# PCIE1_CORE_DBN_CFG_PCIE_CORE register map
Vendor: Texas Instruments
Peripheral module from a debugger description file (folder J721S2).
Registers are 32-bit, read-write, reset 0x0 unless marked. A register's access mark holds for its fields unless they carry their own. Offsets are as the file gives them; lines under a group give offsets from that group; [hi:lo] are bit positions; {n}, {i} and the like mark numbered series; 'fields as' and 'values as' point back to an identical list; <NAME> marks a mode.

## PCIE1_CORE_DBN_CFG_PCIE_CORE (part 1 of 7)
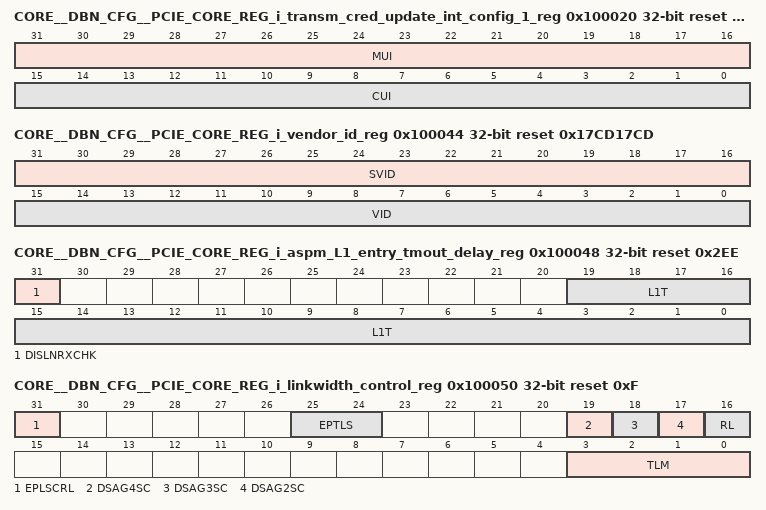
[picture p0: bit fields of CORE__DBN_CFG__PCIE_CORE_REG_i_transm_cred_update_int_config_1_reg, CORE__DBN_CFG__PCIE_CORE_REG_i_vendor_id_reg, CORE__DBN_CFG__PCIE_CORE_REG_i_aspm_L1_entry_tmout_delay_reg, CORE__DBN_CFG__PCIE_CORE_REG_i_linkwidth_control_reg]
0x100020 CORE__DBN_CFG__PCIE_CORE_REG_i_transm_cred_update_int_config_1_reg reset 0x3AA0004 — This register contains parameters that control how frequently the Controller sends a credit update to the opposite node.
  [31:16] MUI — Maximum credit update interval for all transactions. If no new credit has become available since the last update, the Controller will repeat the last update after this interval. This is to recover from any losses of credit update packets. The value is in units of 16 ns. This field could be re-written by the internal logic when the negotiated link width or link speed changes, to correspond to the default values defined in defines.h. The user may override this default value by writing into this register field. The value written will be lost on a change in the negotiated link width/speed.
  [15:0] CUI — Minimum credit update interval for Completion packets. The Controller follows this minimum interval between issuing completion credit updates on the link. This is to limit the bandwidth use of credit updates. If new credit becomes available in the receive FIFO since the last update was sent, the Controller will issue a new update only after this interval has elapsed since the last update. The value is in units of 16 ns. This parameter is not used when the Completion credit is infinity.
0x100024 CORE__DBN_CFG__PCIE_CORE_REG_i_L0S_timeout_limit_reg reset 0x177 — This register defines the timeout value for transitioning to the L0S power state. If the transmit side has been idle for this interval, the Controller will transmit the idle sequence on the link and transition the state of the link to L0S .
  [15:0] LT — Contains the timeout value [in units of 16 ns] for transitioning to the L0S power state. Setting this parameter to 0 permanently disables the transition to the L0S power state.
0x100028 CORE__DBN_CFG__PCIE_CORE_REG_i_transmit_tlp_count_reg access not given — This register contains the number of Transaction-Layer packets transmitted by the Controller on the link since the register was last reset. This counter saturates on reaching a count of all 1's. Writing all 1's to this register causes it to be reset to 0.
  [31:0] TTC — Count of TLPs transmitted (access R/W1TC)
0x10002C CORE__DBN_CFG__PCIE_CORE_REG_i_transmit_tlp_payload_dword_count_reg access not given — This register contains the aggregate number of payload double-words transmitted in Transaction-Layer Packets by the Controller on the link since the register was last reset. This counter saturates on reaching a count of all 1's. Writing all 1's to this register causes it to be reset to 0.
  [31:0] TTPBC — Count of TLPs payload Dwords transmitted (access R/W1TC)
0x100030 CORE__DBN_CFG__PCIE_CORE_REG_i_receive_tlp_count_reg access not given — This register contains the number of Transaction-Layer packets received by the Controller from the link since the register was last reset. This counter saturates on reaching a count of all 1's. Writing all 1's to this register causes it to be reset to 0.
  [31:0] RTC — Count of TLPs received (access R/W1TC)
0x100034 CORE__DBN_CFG__PCIE_CORE_REG_i_receive_tlp_payload_dword_count_reg access not given — This register contains the aggregate number of payload double-words received in Transaction-Layer packets by the Controller from the link since the register was last reset. This counter saturates on reaching a count of all 1's. Writing all 1's to this register causes it to be reset to 0.
  [31:0] RTPDC — Count of TLP payload Dwords received (access R/W1TC)
0x100038 CORE__DBN_CFG__PCIE_CORE_REG_i_compln_tmout_lim_0_reg reset 0xBEBC20 — This register contains the timeout value used to detect a completion timeout event for a request originated by the Controller from it master interface, when sub-range 1 is programmed in the Device Control 2 Register.
  [23:0] CTL — Timeout limit for completion timers [in 4 ns cycles]. Default value is 50 ms in 4 ns cycles. Please note that there could be a variation of 0 to +8us on the programmed Completion Timeout.
0x10003C CORE__DBN_CFG__PCIE_CORE_REG_i_compln_tmout_lim_1_reg reset 0x2FAF080 — This register contains the timeout value used to detect a completion timeout event for a request originated by the Controller from its master interface, when sub-range 2 is programmed in the Device Control 2 Register.
  [27:0] CTL — Timeout limit for completion timers [in 4 ns cycles]. Default value is 200ms in 4ns cycles. Please note that there could be a variation of 0 to +8us on the programmed Completion Timeout.
0x100040 CORE__DBN_CFG__PCIE_CORE_REG_i_L1_st_reentry_delay_reg — This register specifies the time the Controller will wait before it re-enters the L1 state if its link partner transitions the link to L0 while all the Functions of the Controller are in D3 power state. The Controller will change the power state of the link from L0 to L1 if no activity is detected both on the transmit and receive sides before this interval, while all Functions are in D3 state and the link is in L0. Setting this register to 0 disables re-entry to L1 state if the link partner returns the link to L0 from L1 when all the Functions of the Controller are in D3 state. This register controls only the re-entry to L1. The initial transition to L1 always occurs when all of the Functions of the Controller are set to the D3 state.
  [31:0] L1RD — Delay to re-enter L1 after no activity [in units of 16 ns].
0x100044 CORE__DBN_CFG__PCIE_CORE_REG_i_vendor_id_reg reset 0x17CD17CD — This register contains the Vendor ID and Subsystem Vendor ID that the device advertises during its enumeration of the PCI configuration space.
  [31:16] SVID — Subsystem Vendor ID
  [15:0] VID — Vendor ID
0x100048 CORE__DBN_CFG__PCIE_CORE_REG_i_aspm_L1_entry_tmout_delay_reg reset 0x2EE — This register defines the timeout value for transitioning to the L1 power state under Active State Power management. If the transmit side has been idle for this interval, the Controller will initiate a transition of its link to the L1 power state.
  [31] DISLNRXCHK — This bit is used to configure the ASPM L1 Entry mechanism: 1: Link is checked for IDLE only on the TX to determine ASPM L1 Entry. ASPM L1 entry is initiated if no TLP is transmitted for the L1 timeout period. 0: Link is checked for IDLE both on the TX and RX to determine ASPM L1 Entry. ASPM L1 entry is initiated if no TLP is transmitted/received for the L1 timeout period.
  [19:0] L1T — Contains the timeout value[in units of 16 ns] for transitioning to the L1 power state. Setting it to 0 permanently disables the transition to the L1 power state.
0x10004C CORE__DBN_CFG__PCIE_CORE_REG_i_pme_turnoff_ack_delay_reg reset 0x64 — Defines the time interval between the Controller receiving a PME_Turn_Off message from the link and generating an ack for it.
  [15:0] PTOAD — Time in microseconds between the Controller receiving a PME_TurnOff message TLP and the Controller sending a PME_TO_Ack response to it. This field must be set to a non-zero value in order for the Controller to send a response. Setting this field to 0 suppresses the Controller's response to PME_TurnOff message, so that the client may transmit the PME_TO_Ack message through the master interface.
0x100050 CORE__DBN_CFG__PCIE_CORE_REG_i_linkwidth_control_reg reset 0xF — This register can be used to retrain the link to a different width, without bringing the link down. This register can also be used to retrain the link to a different speed, without bringing the link down.
  [31] EPLSCRL — Writing a 1 into this field results in the Controller re-training the link to change its speed. When setting this bit to 1, the software must also set the EP Target Link Speed field to indicate the speed that the EP desires to change on the link. The EP Controller will attempt to change the link to this speed. This bit is cleared by the internal logic of the Controller after the re-training has been completed and link has reached the L0 state. Software must wait for the bit to be clear before setting it again to change the link speed.
  [25:24] EPTLS — This field contains the Link Speed that the EP intends to change to during the re-training. Client needs to ensure that this field is programmed to a speed which is lesser than or equal to the Target Link Speed field of PF0 Configuration Link Control 2 Register. Client also needs to ensure that this does not exceed PCIE_GENERATION_SEL strap input. Defined encodings of this field are: 00 - GEN1 01 - GEN2 10 - GEN3 11 - GEN4
  [19] DSAG4SC — This bit is used Only in RP mode. This bit is not used in EP mode of the Controller. During initial link training, if both components advertise Gen4 capability and if Gen3 speed change, equalization was successful, the Controller [RP] autonomously initiates Gen3 to Gen4 speed change, equalization. If Gen4 autonomous speed change/equalization was unsuccessful, then the Link transitions back to Gen3 L0. Software can re-initiate Gen4 speed change. Autonomous Speed Change to Gen4 can be disabled by programming this bit to 1. Note: If Disable Auto Gen3 Speed Change is disabled, then Auto Gen4 Speed Change must also be disabled by setting this bit to 1.
  [18] DSAG3SC — This bit is used Only in RP mode. This bit is not used in EP mode of the Controller. During initial link training, if both components advertise Gen3 capability, the Controller [RP] autonomously initiates Gen1 to Gen3 speed change, equalization. If Gen3 autonomous speed change/equalization was unsuccessful, then the Link transitions back to Gen1 L0. Software can re-initiate Gen3 speed change. Autonomous Speed Change to Gen3 can be disabled by programming this bit to 1.
  [17] DSAG2SC — This bit is used Only in RP mode. This bit is not used in EP mode of the Controller. During initial link training, if both components advertise Gen2 capability and if Gen2 is the highest common supported speed the Controller [RP] autonomously initiates Gen1 to Gen2 speed change. If Gen2 autonomous speed change was unsuccessful, then the Link transitions back to Gen1 L0. Software can re-initiate Gen2 speed change. Autonomous Speed Change to Gen2 can be disabled by programming this bit to 1.
  [16] RL — Writing a 1 into this field results in the Controller re-training the link to change its width. When setting this bit to 1, the software must also set the target lane-map field to indicate the lanes it desires to be part of the link. The Controller will attempt to form a link with this set of lanes. The link formed at the end of the retraining may include all of these lanes [if both nodes agree on them during re-training], or the largest subset that both sides were able to activate. This bit is cleared by the internal logic of the Controller after the re-training has been completed and link has reached the L0 state. Software must wait for the bit to be clear before setting it again to change the link width.
  [3:0] TLM — This field contains the bitmap of the lanes to be included in forming the link during the re-training. 0001 - Retrain to a x1 link 0011 - Retrain to a x2 link 1111 - Retrain to a x4 link If the target lane map includes lanes that were inactive when retraining is initiated, then both the Controller and its link partner must support the LinkWidth Upconfigure Capability to be able to activate those lanes. In RC Mode, the user can check if the remote node has this capability by reading the Remote Link Upconfigure Capability Status bit in Physical Layer Configuration Register 0 after the link first came up.
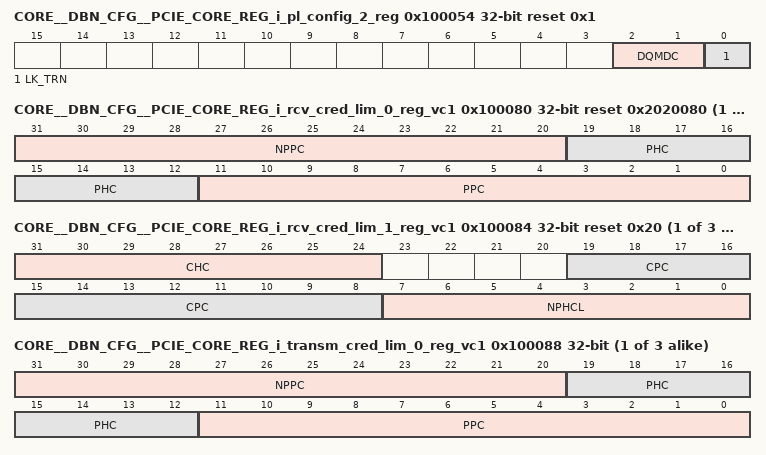
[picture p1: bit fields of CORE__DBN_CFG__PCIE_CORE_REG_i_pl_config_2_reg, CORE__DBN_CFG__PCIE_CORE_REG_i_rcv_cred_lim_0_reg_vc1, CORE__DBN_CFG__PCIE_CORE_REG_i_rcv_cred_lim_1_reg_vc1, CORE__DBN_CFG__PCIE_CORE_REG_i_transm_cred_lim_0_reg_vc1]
0x100054 CORE__DBN_CFG__PCIE_CORE_REG_i_pl_config_2_reg reset 0x1 — This register controls various LTSSM related capabilities.
  [2:1] DQMDC — As per PCIe specification, All Receivers must meet the the Z-RX-DC specification for 2.5 GT/s within 1ms of entering Detect.Quiet LTSSM substate. The LTSSM must stay in this substate until the ZRX-DC specification for 2.5 GT/s is met. This register field can be used to program the minimum time that LTSSM waits on entering Detect.Quiet state. 00 : 0us minimum wait time in Detect.Quiet state. 01 : 100us minimum wait time in Detect.Quiet state. 10 : 1ms minimum wait time in Detect.Quiet state. 11 : 2ms minimum wait time in Detect.Quiet state.
  [0] LK_TRN — This bit is AND'ed with the input LINK_TRAINING_ENABLE strap to enable Link Training.
0x100070 CORE__DBN_CFG__PCIE_CORE_REG_i_multi_vc_conrol_reg reset 0x2 — This register contains control bits to control certain multi VC features
  [1] WAIT_4_ALL_VC_CC_RDY — When this bit is set, the controller waits for credits to be available to be able to send atleast 1 max payload TLP in all enabled VCs. When this bit is not set, the controller waits for credits to be available to be able to send atleast 1 max payload TLP in any of the enabled VCs [PCI-SIG recommedned].
0x100074 CORE__DBN_CFG__PCIE_CORE_REG_i_sris_control_reg — This register contains control bits to enable the SRIS operation in the PHY Layer
  [0] SRISE — Setting this bit enables SRIS mode in the PHY layer. This bit should be changed before link training begins by holding the LINK_TRAINING_ENABLE input to 1'b0. When SRIS is disabled using this bit the Lower SKP OS Generation Supported Speeds Vector and Lower SKP OS Reception Supported Speeds Vector in the Link Capabilities Register 2 will be forced to ZERO. The default value of this register can be controlled using the SRIS_ENABLE strap input.
{0x100070+0x10*i} CORE__DBN_CFG__PCIE_CORE_REG_i_rcv_cred_lim_0_reg_vc{i} reset 0x2020080 (i=1..3) — This register contains the initial credit limits advertised by the Controller during th DL initialization. If the fields of this register are modified, the link must be re-trained to re-initialize the DL for the modified settings to take effect. The credit limit fields in this register can be programmed to any value lesser than or equal to the respective default values. The default values are set to advertise the full size of the receive buffers. If a value of 0x00 is programmed, it implies infinite credit. Note: This may result in receiver overflow if received data is back pressured on the Client interface.
  [31:20] NPPC — Non-Posted payload credit limit advertised by the Controller for VC {i} . This field is in units of 4 DWords, 16 DWords or 64 DWords based on the Local Posted Payload Credit Scale for VC {i}. 00b => [units of 4 DWords] 01b => [units of 4 DWords] 10b => [units of 16 DWords] 11b => [units of 64 DWords] Note: When Scaled FLow Control is Activated, the programmed credit value is advertised in the InitFC DLLPs. Else, the programmed credit value is internally normalized to units of 4 DW and then advertised in the InitFC DLLPs. Caution: The programmed Header and Payload credit values must not exceed the actual size of the Receive Buffer.
  [19:12] PHC — Posted header credit limit advertised by the Controller for VC {i}. This field is in units of 1, 4 or 16 Packet Headers based on the Local Posted Header Credit Scale for VC {i}. 00b => [units of 1 Packet Header] 01b => [units of 1 Packet Header] 10b => [units of 4 Packet Headers] 11b => [units of 16 Packet Headers] Note: When Scaled FLow Control is Activated, the programmed credit value is advertised in the InitFC DLLPs. Else, the programmed credit value is internally normalized to units of [1 Packet Header] and then advertised in the InitFC DLLPs. Note: Packet Header represents one maximum-size TLP Header + TLP Digest + maximum number of EndEnd TLP Prefixes permitted in a TLP. Caution: The programmed Header and Payload credit values must not exceed the actual size of the Receive Buffer.
  [11:0] PPC — Posted payload credit limit advertised by the Controller for VC {i}. This field is in units of 4 DWords, 16 DWords or 64 DWords based on the Local Posted Payload Credit Scale for VC {i}. 00b => [units of 4 DWords] 01b => [units of 4 DWords] 10b => [units of 16 DWords] 11b => [units of 64 DWords] Note: When Scaled FLow Control is Activated, the programmed credit value is advertised in the InitFC DLLPs. Else, the programmed credit value is internally normalized to units of 4 DW and then advertised in the InitFC DLLPs. Caution: The programmed Header and Payload credit values must not exceed the actual size of the Receive Buffer.
{0x100074+0x10*i} CORE__DBN_CFG__PCIE_CORE_REG_i_rcv_cred_lim_1_reg_vc{i} reset 0x20 (i=1..3) — This register contains the initial credit limits advertised by the Controller during the DL initialization. If the fields of this register are modified, the link must be re-trained to re-initialize the DL for the modified settings to take effect. The credit limit fields in this register can be programmed to any value lesser than or equal to the respective default values. The default values are set to advertise the full size of the receive buffers. If a value of 0x00 is programmed, it implies infinite credit. Note: This may result in receiver overflow if received data is back pressured on the Client interface.
  [31:24] CHC — Completion header credit limit advertised by the Controller for VC {i} [in number of packets]. This field is in units of 1, 4 or 16 Packet Headers based on the Local Posted Header Credit Scale for VC {i}. 00b => [units of 1 Packet Header] 01b => [units of 1 Packet Header] 10b => [units of 4 Packet Headers] 11b => [units of 16 Packet Headers] Note: When Scaled FLow Control is Activated, the programmed credit value is advertised in the InitFC DLLPs. Else, the programmed credit value is internally normalized to units of [1 Packet Header] and then advertised in the InitFC DLLPs. Note: Packet Header represents one maximum-size TLP Header + TLP Digest + maximum number of EndEnd TLP Prefixes permitted in a TLP. Caution: The programmed Header and Payload credit values must not exceed the actual size of the Receive Buffer.
  [19:8] CPC — Completion payload credit limit advertised by the Controller for VC {i} . This field is in units of 4 DWords, 16 DWords or 64 DWords based on the Local Posted Payload Credit Scale for VC {i}. 00b => [units of 4 DWords] 01b => [units of 4 DWords] 10b => [units of 16 DWords] 11b => [units of 64 DWords] Note: When Scaled FLow Control is Activated, the programmed credit value is advertised in the InitFC DLLPs. Else, the programmed credit value is internally normalized to units of 4 DW and then advertised in the InitFC DLLPs. Caution: The programmed Header and Payload credit values must not exceed the actual size of the Receive Buffer.
  [7:0] NPHCL — Non-Posted header credit limit advertised by the Controller for VC {i} [in number of packets]. This field is in units of 1, 4 or 16 Packet Headers based on the Local Posted Header Credit Scale for VC {i}. 00b => [units of 1 Packet Header] 01b => [units of 1 Packet Header] 10b => [units of 4 Packet Headers] 11b => [units of 16 Packet Headers] Note: When Scaled FLow Control is Activated, the programmed credit value is advertised in the InitFC DLLPs. Else, the programmed credit value is internally normalized to units of [1 Packet Header] and then advertised in the InitFC DLLPs. Note: Packet Header represents one maximum-size TLP Header + TLP Digest + maximum number of EndEnd TLP Prefixes permitted in a TLP. Caution: The programmed Header and Payload credit values must not exceed the actual size of the Receive Buffer.
{0x100078+0x10*i} CORE__DBN_CFG__PCIE_CORE_REG_i_transm_cred_lim_0_reg_vc{i} ro (i=1..3) — This register contains the initial credit limits received from the opposite node during the DL initialization. It is a read-only register.
  [31:20] NPPC — Non-Posted payload credit limit received by the Controller for Link 0 . This field is in units of 4 DWords, 16 DWords or 64 DWords based on the Remote Posted Payload Credit Scale for VC {i}. 00b => [units of 4 DWords] 01b => [units of 4 DWords] 10b => [units of 16 DWords] 11b => [units of 64 DWords]
  [19:12] PHC — Posted header credit limit received by the Controller for this link . This field is in units of 1, 4 or 16 Packet Headers based on the Remote Posted Header Credit Scale for VC {i}. 00b => [units of 1 Packet Header] 01b => [units of 1 Packet Header] 10b => [units of 4 Packet Headers] 11b => [units of 16 Packet Headers] Note: Packet Header represents one maximum-size TLP Header + TLP Digest + maximum number of EndEnd TLP Prefixes permitted in a TLP.
  [11:0] PPC — Posted payload credit limit received by the Controller for this link . This field is in units of 4 DWords, 16 DWords or 64 DWords based on the Remote Posted Payload Credit Scale for VC {i}. 00b => [units of 4 DWords] 01b => [units of 4 DWords] 10b => [units of 16 DWords] 11b => [units of 64 DWords]
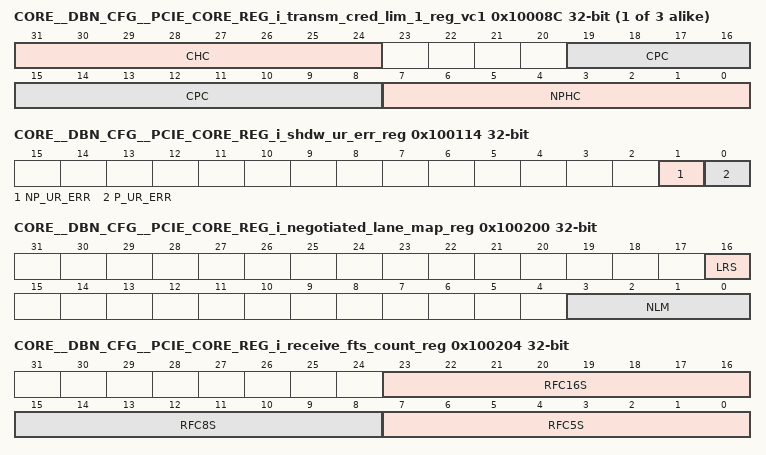
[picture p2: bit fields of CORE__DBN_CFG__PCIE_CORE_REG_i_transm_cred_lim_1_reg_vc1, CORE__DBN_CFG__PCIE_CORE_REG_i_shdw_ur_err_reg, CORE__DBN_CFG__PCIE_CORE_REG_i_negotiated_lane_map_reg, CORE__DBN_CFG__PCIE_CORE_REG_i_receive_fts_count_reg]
{0x10007C+0x10*i} CORE__DBN_CFG__PCIE_CORE_REG_i_transm_cred_lim_1_reg_vc{i} ro (i=1..3) — This register contains the initial credit limits received from the opposite node during the DL initialization. It is a read-only register.
  [31:24] CHC — Completion header credit limit received by the Controller for VC {i} . This field is in units of 1, 4 or 16 Packet Headers based on the Remote Posted Header Credit Scale for VC {i}. 00b => [units of 1 Packet Header] 01b => [units of 1 Packet Header] 10b => [units of 4 Packet Headers] 11b => [units of 16 Packet Headers] Note: Packet Header represents one maximum-size TLP Header + TLP Digest + maximum number of EndEnd TLP Prefixes permitted in a TLP.
  [19:8] CPC — Completion payload credit limit received by the Controller for VC {i} . This field is in units of 4 DWords, 16 DWords or 64 DWords based on the Remote Posted Payload Credit Scale for VC {i}. 00b => [units of 4 DWords] 01b => [units of 4 DWords] 10b => [units of 16 DWords] 11b => [units of 64 DWords]
  [7:0] NPHC — Non-Posted header credit limit received by the Controller for VC {i} . This field is in units of 1, 4 or 16 Packet Headers based on the Remote Posted Header Credit Scale for VC {i}. 00b => [units of 1 Packet Header] 01b => [units of 1 Packet Header] 10b => [units of 4 Packet Headers] 11b => [units of 16 Packet Headers] Note: Packet Header represents one maximum-size TLP Header + TLP Digest + maximum number of EndEnd TLP Prefixes permitted in a TLP.
0x1000F0 CORE__DBN_CFG__PCIE_CORE_REG_i_fc_init_delay_reg reset 0x64 — This register defines the delay value in between successive FC_INIT DLLPs for VCx.
  [15:0] FCINITDLY — Delay between successive sets of P, NP, CPL FC_INIT DLLP transmissions for VCx.
{0x100100+4i} CORE__DBN_CFG__PCIE_CORE_REG_i_shdw_hdr_log_{i}_reg (i=0..3)
  [31:0] SHDW_HDR_LOG_{i} — The value here will be reflected in the target function's header log register when f/w sets any bit in the the shadow error register. If the header log is already set in the function's AER space, the value here may not get written and a header log overflow bit would get set. This register holds [{32i+31}:{32i}] value of the TLP header.
0x100110 CORE__DBN_CFG__PCIE_CORE_REG_i_shdw_func_num_reg
  [7:0] SHDW_FUNC_NUM — The value here will be the target function number when f/w sets any bit in the shadow error register.
0x100114 CORE__DBN_CFG__PCIE_CORE_REG_i_shdw_ur_err_reg wo — Shadow register to create UR error via local f/w. Please make sure this register is written to last, after writing to all the header log and function number registers. A write to this register with any bits set, will internally create a single cycle pulse with the corresponding error type and the header log will reflect the value written in the shadow header log registers.
  [1] NP_UR_ERR — If this bit is set, the corresponding non-posted UR error bits will be set in the AER and device status registers of the target function.
  [0] P_UR_ERR — If this bit is set, the corresponding posted UR error bits will be set in the AER and device status registers of the target function.
0x100140 CORE__DBN_CFG__PCIE_CORE_REG_i_pm_clk_frequency_reg reset 0x19 — This register should be programmed with the frequency of the PM_CLK input to the Controller. The Controller supports the frequency range of 2MHz to 60MHz for PM_CLK. The reset value reflects the PM_CLK frequency chosen during Controller configuration. NOTE: PM_CLK will be timed at 60Mhz and the Controller SDC file will be generated accordingly. If timing is to be closed at a different frequency, then the user needs to update the SDC accordingly.
  [7:0] PMCLKFRQ — This field specifies the PM_CLK Frequency selected. The encoding is described below: 000000: Reserved 000001: Reserved 000010: PM_CLK is 2 MHz 000011: PM_CLK is 3 MHz 000100: PM_CLK is 4 MHz 000101: PM_CLK is 5 MHz .. 111010: PM_CLK is 58 MHz 111011: PM_CLK is 59 MHz 111100: PM_CLK is 60 MHz 111101 : Reserved 111110 : Reserved 111111 : Reserved .
{0x100140+4i} CORE__DBN_CFG__PCIE_CORE_REG_i_debug_dllp_count_gen{i}_reg ro (i=1..4) — This register indicates the total number of DLLPs received by the Controller in GEN{i}. This counter rolls over back to 0 after 4G DLLPs are received. This register can be used for Debug purposes.
  [31:0] DLLPCNT{i} — Reflects the total number of DLLPs received by the Controller at GEN{i} speed.
0x100158 CORE__DBN_CFG__PCIE_CORE_REG_i_vendor_defined_message_tag_reg — The 8-bit Tag field of the Outbound Vendor Defined Messages, transmitted by the Controller, can be programmed in this register.
  [7:0] VDMTAG — The Controller will use the tag programed in this register for all Outbound Vendor Defined Messages.
0x100200 CORE__DBN_CFG__PCIE_CORE_REG_i_negotiated_lane_map_reg ro — This register contains a map of the active lanes used by the Controller to form the link during link training. It also contains a bit to indicate whether the Controller reversed the lane number on its lanes during link training.
  [16] LRS — This bit set by the Controller at the end of link training if the LTSSM had to reverse the lane numbers to form the link.
  [3:0] NLM — Bit i of this field is set to 1 at the end of link training if Lane i is part of the PCIe link. The value of this field is valid only when the link is in L0 or L0s states.
0x100204 CORE__DBN_CFG__PCIE_CORE_REG_i_receive_fts_count_reg ro — This register contains the FTS count values received from the link partner during link training for use at the 5 GT/s 8 GT/s and 16 GT/s speeds. These values determine the number of Fast Training Sequences transmitted by the Controller when it exits the L0s link power state.
  [23:16] RFC16S — FTS count received from the other side during link training for use at the 16 GT/s link speed. The Controller transmits this many FTS sequences while exiting the L0S state, when operating at the 16 GT/s speed.
  [15:8] RFC8S — FTS count received from the other side during link training for use at the 8 GT/s link speed. The Controller transmits this many FTS sequences while exiting the L0S state, when operating at the 8 GT/s speed.
  [7:0] RFC5S — FTS count received from the other side during link training for use at the 5 GT/s link speed. The Controller transmits this many FTS sequences while exiting the L0S state, when operating at the 5 GT/s speed.
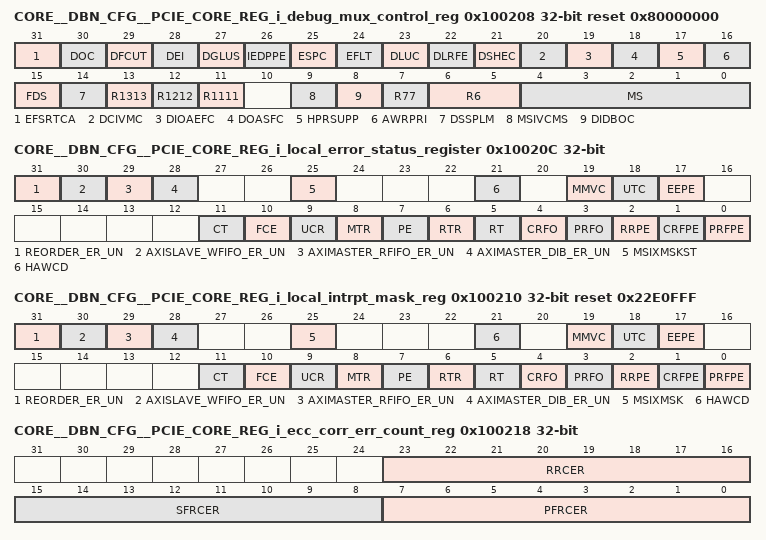
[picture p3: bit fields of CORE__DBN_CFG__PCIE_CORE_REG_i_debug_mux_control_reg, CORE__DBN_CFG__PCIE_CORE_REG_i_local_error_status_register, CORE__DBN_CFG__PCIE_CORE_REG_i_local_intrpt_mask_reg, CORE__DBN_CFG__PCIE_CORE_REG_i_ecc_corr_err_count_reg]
0x100208 CORE__DBN_CFG__PCIE_CORE_REG_i_debug_mux_control_reg access per field reset 0x80000000
  [31] EFSRTCA rw — Setting this bit to 0 causes all the enabled Functions to report an error when a Type-1 configuration access is received by the Controller, targeted at any Function. Setting it to 1 limits the error reporting to the type-0 Function whose number matches with the Function number specified in the request. If the Function number in the request refers to an unimplemented or disabled Function, all enabled Functions report the error regardless of the setting of this bit.
  [30] DOC rw — Setting this bit to 1 disables the ordering check in the Controller between Completions and Posted requests received from the link.
  [29] DFCUT rw — When this bit is 0, the Controller will time out and re-train the link when no Flow Control Update DLLPs are received from the link within an interval of 128 us. Setting this bit to 1 disables this timeout. When the advertised receive credit of the link partner is infinity for the header and payload of all credit types, this timeout is always suppressed. The setting of this bit has no effect in this case. This bit should not be set during normal operation, but is useful for testing.
  [28] DEI rw — Setting this bit to 1 disables the inferring of electrical idle in the L0 state. Electrical idle is inferred when no flow control updates and no SKP sequences are received within an interval of 128 us. This bit should not be set during normal operation, but is useful for testing.
  [27] DGLUS rw — Setting this bit to 1 disables the update of the LFSRs in the Gen3 descramblers of the Controller, from the values received in SKP sequences. This bit should not be set during normal operation, but is useful for testing.
  [26] IEDPPE rw — When set to 1, this bit inverts the parity bits generated by the Controller for end-to-end data protection. This will result in the inversion of parity bits for data payloads delivered through the HAL Target Interface request descriptor. This bit is to be used for diagnostics only, and should not be set during normal operation.
  [25] ESPC rw — When this bit is set to 1, the Controller will capture the Slot Power Limit Value and Slot Power Limit Scale parameters from a Set_Slot_Power_Limit message received in the Device Capabilities Register. When this bit is 0, the capture is disabled. This bit is valid only when the Controller is configured as an EndPoint. It has no effect when the Controller is a Root Complex.
  [24] EFLT rw — This bit is provided to shorten the link training time to facilitate fast simulation of the design, especially at the gate level. Enabling this bit has the following effects: 1. The 1 ms, 2 ms, 12 ms, 24 ms, 32 ms and 48 ms timeout intervals in the LTSSM are shortened by a factor of 500. 2. In the Polling.Active state of the LTSSM, only 16 training sequences are required to be transmitted [Instead of 1024] to make the transition to the Configuration state. This bit should not be set during normal operation of the Controller.
  [23] DLUC rw — The user may set this bit to turn off the link upconfigure capability of the Controller. Setting this bit prevents the Controller from advertising the link upconfigure capability in training sequences transmitted in the Configuration.Complete state. In addition, setting this bit causes the Controller to put the unused lanes into Turn Off mode. When disable_link_upconfigure_capability==1: Controller drives PIPE_TX_ELEC_IDLE==1 AND PIPE_TX_COMPLIANCE==1 for the Unused upper lanes. The Unused upper lanes are put into Turn Off mode by the PHY as per PIPE specification. When disable_link_upconfigure_capability==0: Controller drives PIPE_TX_ELEC_IDLE==1 AND PIPE_TX_COMPLIANCE==0 for the Unused upper lanes. The Unused upper lanes are put into Electrical Idle by the PHY.
  [22] DLRFE rw — When this bit is 1, the Controller will not transition its LTSSM into the Recovery state when it detects a Framing Error at 8 GT/s or 16 GT/s speed [as defined in Section 4.2.2.3.3 of the PCIe Base Specification 3.0. This bit must normally be set to 0 so that a Framing Error will cause the LTSSM to enter Recovery. The setting of this bit has no effect on the operation of the Controller at 2.5 and 5 GT/s speeds.
  [21] DSHEC rw — When this bit is 0, the Controller will signal a framing error if it detects a sync header error in the received blocks at 8 GT/s or 16 GT/s speed [A 00 or 11 binary setting of the sync header on the received blocks in any lane constitutes a framing error]. Setting this bit to 1 suppresses this error check. This bit should normally be set to 0, as the sync header check is mandatory in the PCIe 3.0 Specifications.
  [20] DCIVMC rw — When this bit is 1, the Controller will not check for invalid message codes. This bit should normally set to 0, as the invalid message code checking is mandatory in the PCIe 3.0 specifications.
  [19] DIOAEFC rw — When this bit is 1, the Controller will not check for illegal OS after EDS as part of Gen3 Framing Error Checks. This bit should normally set to 0, as this is a mandatory Gen3 Framing Error check in the PCIe 3.0 specifications.
  [18] DOASFC rw — When this bit is 1, the Controller will not check for OS after SKIP OS as part of Gen3 Framing Error Checks. This bit should normally set to 0, as this is a mandatory Gen3 Framing Error check in the PCIe 3.0 specifications.
  [17] HPRSUPP rw — When this bit is 1, data path parity check is disabled on the TX side of the Controller.
  [16] AWRPRI rw — When this bit is 1, the AXI bridge places a write request on the HAL Master interface in preference over a read request if both AXI write and AXI read requests are available to be asserted on the same clock cycle.
  [15] FDS rw — Disable Scrambling/Descrambling in Gen1/Gen2.
  [14] DSSPLM rw — Disable sending Set Slot Power Limit Message if the Slot Capabilitied register is configured
  [13] R1313 ro
  [12] R1212 ro
  [11] R1111 rw — When this bit is 1, Disable Client TX MUX Completion and PNP request arbitartion,roundrobin priority logic added to prevent PNP requests from starving when completions are present
  [9] MSIVCMS rw — Sets the mode of generating MSI_VECTOR_COUNT output for all functions. 0 - MSI_VECTOR_COUNT always outputs the configured value of MSI Multiple Message Enable[2:0] register. 1 - MSI_VECTOR_COUNT outputs the lesser of the MSI Multiple Message Enable[2:0] and MSI Multiple Message Capable[2:0] This mode can be used to handle any programming error form the Host software.
  [8] DIDBOC rw — Setting this bit to 1 disables the ID Based Ordering check in the Controller between Completions and Posted requests received from the link.
  [7] R77 rw — This bit should be set to 0 for backward compatibility.
  [6:5] R6 ro
  [4:0] MS rw — Bits 4:3 select the module and bits 2:0 select the group of signals within the module that are driven on the debug bus. The assignments of signals on the debug outputs of the Controller are given in Appendix B.
0x10020C CORE__DBN_CFG__PCIE_CORE_REG_i_local_error_status_register access not given — This register contains the status of the various events, errors and abnormal conditions in the Controller. Any of the status bits can be reset by writing a 1 into the bit position. This register does not capture any errors signaled by remote devices using PCIe error messages when the Controller is operating in the RC mode. Unless masked by the setting of the Local Interrupt Mask Register, the occurrence of any of these conditions causes the Controller to activate the LOCAL_INTERRUPT output.
  [31] REORDER_ER_UN — This indicates an uncorrectbale axi slave reorder ram parity/ecc error (access R/W1TC)
  [30] AXISLAVE_WFIFO_ER_UN — This indicates an uncorrectbale axi slave write fifo ram parity/ecc error (access R/W1TC)
  [29] AXIMASTER_RFIFO_ER_UN — This indicates an uncorrectbale axi master write fifo ram parity/ecc error (access R/W1TC)
  [28] AXIMASTER_DIB_ER_UN — This indicates an uncorrectbale axi slave write fifo ram parity/ecc error (access R/W1TC)
  [25] MSIXMSKST — This interrupt status bit is used when MSIX Function Mask Enhanced Interrupt Enable bit is set to 0 by the User. This status bit indicates that the MSIX Function Mask bit of any function, PF or VF, was programmed or configured by Local Firmware Or Host SW. (access R/W1TC)
  [21] HAWCD — This interrupt status bit indicates that the Host toggled the Hardware Autonomous Width Change bit in the Link Control Register through a Config Write. Upon this interrupt, the Client firmware must read the Link Control Register to check the value set by Host in the Hardware Autonomous Width Change bit. The Host Software may disable autonomous width change by setting Hardware Autonomous Width Disable bit in the Link Control register. If disabled by the Host and if the Endpoint firmware had initiated an autonomous width downsizing prior to this interrupt, then the local Client firmware is responsible to upconfigure the Link to go to its full functional width by initiating the link_upconfigure_retrain_link within 1 ms of this interrupt. (access R/W1TC)
  [19] MMVC — This status bit is set whenever the MSI mask register value in the MSI capability register changes value in ANY of the functions in the controller (access R/W1TC)
  [18] UTC — Unmapped TC error. (access R/W1TC)
  [17] EEPE — The Controller detected an End to End Parity Error (access R/W1TC)
  [11] CT — A request timed out waiting for completion. (access R/W1TC)
  [10] FCE — An error was observed in the flow control advertisements from the other side. (access R/W1TC)
  [9] UCR — Unexpected Completion received from the link. (access R/W1TC)
  [8] MTR — Malformed TLP received from the link. (access R/W1TC)
  [7] PE — Phy error detected on receive side. This bit is set when an error is detected in the receive side of the Physical Layer of the Controller [e.g. a bit error or coding violation]. This bit is set upon any of the following errors: [1] PHY reported 8B10B error, Disparity Error, Elastic Buffer Overflow Error, Underflow Error [2] GEN3 TLP, DLLP Framing Errors [3] OS Block Received Without EDS [4] Data Block Received After EDS [5] Illegal OS Block After EDS [6] OS Block Received After SKIP OS [7] OS Block Received After SDS [8] Sync Header Error [9] Loss of Gen3 Block Alignment This error is not Function-specific.. (access R/W1TC)
  [6] RTR — Replay timer rolled over after 4 transmissions of the same TLP. (access R/W1TC)
  [5] RT — Replay timer timed out (access R/W1TC)
  [4] CRFO — Overflow occurred in the Completion Receive FIFO. (access R/W1TC)
  [3] PRFO — Overflow occurred in the PNP Receive FIFO. (access R/W1TC)
  [2] RRPE — Parity error detected while reading from Replay Buffer RAM. (access R/W1TC)
  [1] CRFPE — Parity error detected while reading from the Completion Receive FIFO RAM. (access R/W1TC)
  [0] PRFPE — Parity error detected while reading from the PNP Receive FIFO RAM. (access R/W1TC)
0x100210 CORE__DBN_CFG__PCIE_CORE_REG_i_local_intrpt_mask_reg reset 0x22E0FFF — This register contains a mask bit for each interrupting condition. Setting the bit to 1 prevents the corresponding condition in the Local Error Status Register from activating the LOCAL_INTERRUPT output.
  [31] REORDER_ER_UN — mask for uncorrectbale axi slave reorder ram parity/ecc error
  [30] AXISLAVE_WFIFO_ER_UN — mask for uncorrectbale axi slave write fifo ram parity/ecc error
  [29] AXIMASTER_RFIFO_ER_UN — mask for uncorrectbale axi master write fifo ram parity/ecc error
  [28] AXIMASTER_DIB_ER_UN — mask for uncorrectbale axi slave write fifo ram parity/ecc error
  [25] MSIXMSK — This bit is used to mask interrupt that indicates that the MSIX Function Mask bit of any function, PF or VF, was programmed or configured by Local Firmware Or Host SW.
  [21] HAWCD — This bit is used to mask interrupt that indicates that the Host toggled the Hardware Autonomous Width Change in the Endpoint Link Control Register through a Config Write.
  [19] MMVC — MSI mask register value in the MSI capability register changes value in ANY of the functions in the controller
  [18] UTC — Unmapped TC error
  [17] EEPE — The Controller detected an End to End Parity Error
  [11] CT — A request timed out waiting for completion.
  [10] FCE — An error was observed in the flow control advertisements from the other side.
  [9] UCR — Unexpected Completion received from the link.
  [8] MTR — Malformed TLP received from the link.
  [7] PE — Phy error detected on receive side.
  [6] RTR — Replay timer rolled over after 4 transmissions of the same TLP.
  [5] RT — Replay timer timed out
  [4] CRFO — Overflow occurred in the Completion Receive FIFO.
  [3] PRFO — Overflow occurred in the PNP Receive FIFO.
  [2] RRPE — Parity error detected while reading from Replay Buffer RAM.
  [1] CRFPE — Parity error detected while reading from the Completion Receive FIFO RAM.
  [0] PRFPE — Parity error detected while reading from the PNP Receive FIFO RAM.
0x100214 CORE__DBN_CFG__PCIE_CORE_REG_i_lcrc_err_count_reg access not given — This register contains the count of the number of TLPs received by the Controller with LCRC errors in them. This is a 16-bit saturating counter that can be reset to 0 by writing all 1's into it.
  [15:0] LEC — Number of TLPs received with LCRC errors. (access R/W1TC)
0x100218 CORE__DBN_CFG__PCIE_CORE_REG_i_ecc_corr_err_count_reg access not given — This register contains the count of the number of ECC errors detected and corrected during reads from the PCIe core external RAMs.
  [23:16] RRCER — Number of correctable errors detected while reading from the Replay Buffer RAM. This is an 8-bit saturating counter that can be cleared by writing all 1's into it. (access R/W1TC)
  [15:8] SFRCER — Number of correctable errors detected while reading from the SC FIFO RAM. This is an 8-bit saturating counter that can be cleared by writing all 1's into it. (access R/W1TC)
  [7:0] PFRCER — Number of correctable errors detected while reading from the PNP FIFO RAM. This is an 8-bit saturating counter that can be cleared by writing all 1's into it. (access R/W1TC)
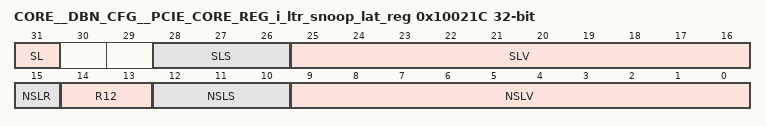
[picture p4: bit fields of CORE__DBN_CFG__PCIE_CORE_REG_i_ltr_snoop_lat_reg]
0x10021C CORE__DBN_CFG__PCIE_CORE_REG_i_ltr_snoop_lat_reg access per field — This register contains the Snoop and No-Snoop Latency parameters used by the Controller when sending Latency Tolerance Reporting (LTR) Message. When the Controller is configured in the EndPoint mode, client software can program these fields to the desired latency settings and then set the Send LTR Message bit in the LTR Message Generation Control Register to send an LTR message to the Root Complex. The fields in this register should not be changed when the Send LTR Message bit in the LTR Message Generation Control Register is 1, which indicates that an LTR message is pending to be transmitted.
  [31] SL rw — The client software must set this bit to 1 to set the Snoop Latency Requirement bit in the LTR message to be sent.
  [28:26] SLS rw — The client software must program this field with the value to be sent in the Snoop Latency Scale field of the LTR message.
  [25:16] SLV rw — The client software must program this field with the value to be sent in the Snoop Latency Value field of the LTR message.
  [15] NSLR rw — The client software must set this bit to 1 to set the No-Snoop Latency Requirement bit in the LTR message to be sent.
  [14:13] R12 ro
  [12:10] NSLS rw — The client software must program this field with the value to be sent in the No-Snoop Latency Scale field of the LTR message.
  [9:0] NSLV rw — The client software must program this field with the value to be sent in the No-Snoop Latency Value field of the LTR message.
